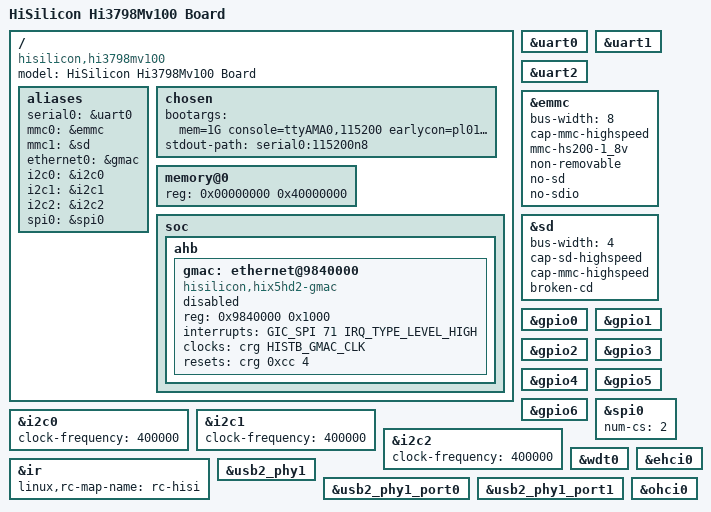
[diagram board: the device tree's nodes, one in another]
// SPDX-License-Identifier: GPL-2.0
/*
 * Device Tree for Hi3798Mv100 board
 * Based on vendor DTS decompiled from hi_kernel.bin
 * Adapted for mainline histb kernel
 */
/dts-v1/;

#include "hi3798mv100.dtsi"

/ {
	model = "HiSilicon Hi3798Mv100 Board";
	compatible = "hisilicon,hi3798mv100", "hisilicon,hi3798";

	aliases {
		serial0 = &uart0;
		mmc0 = &emmc;
		mmc1 = &sd;
		ethernet0 = &gmac;
		i2c0 = &i2c0;
		i2c1 = &i2c1;
		i2c2 = &i2c2;
		spi0 = &spi0;
	};

	chosen {
		bootargs = "mem=1G console=ttyAMA0,115200 earlycon=pl011,mmio32,0xf8b00000 root=/dev/mmcblk0p9 rootfstype=ext4 rootwait";
		stdout-path = "serial0:115200n8";
	};

	memory@0 {
		device_type = "memory";
		reg = <0x00000000 0x40000000>; /* 1GB */
	};
};

/* UART0 - Primary console */
&uart0 {
	status = "okay";
};

/* UART1 */
&uart1 {
	status = "okay";
};

/* UART2 */
&uart2 {
	status = "okay";
};

/* eMMC - Internal storage (non-removable) */
&emmc {
	status = "okay";
	bus-width = <8>;
	cap-mmc-highspeed;
	mmc-hs200-1_8v;
	non-removable;
	no-sd;
	no-sdio;
};

/* SD card slot */
&sd {
	status = "okay";
	bus-width = <4>;
	cap-sd-highspeed;
	cap-mmc-highspeed;
	broken-cd; /* Use polling if no card detect GPIO */
};

/* GPIO blocks used on this board */
&gpio0 { status = "okay"; };
&gpio1 { status = "okay"; };
&gpio2 { status = "okay"; };
&gpio3 { status = "okay"; };
&gpio4 { status = "okay"; };
&gpio5 { status = "okay"; };
&gpio6 { status = "okay"; };

/* I2C buses */
&i2c0 {
	status = "okay";
	clock-frequency = <400000>;
};

&i2c1 {
	status = "okay";
	clock-frequency = <400000>;
};

&i2c2 {
	status = "okay";
	clock-frequency = <400000>;
};

/* SPI0 */
&spi0 {
	status = "okay";
	num-cs = <2>;
};

/* Watchdog */
&wdt0 {
	status = "okay";
};

/* IR receiver */
&ir {
	status = "okay";
	linux,rc-map-name = "rc-hisi";
};

// SPDX-License-Identifier: GPL-2.0
/*
 * GMAC overlay for Hi3798Mv100
 * The mainline dtsi doesn't include the GMAC node yet,
 * so we define it based on vendor data.
 */

/ {
	soc {
		ahb {
			gmac: ethernet@9840000 {
				compatible = "hisilicon,hix5hd2-gmac";
				reg = <0x9840000 0x1000>;
				interrupts = <GIC_SPI 71 IRQ_TYPE_LEVEL_HIGH>;
				clocks = <&crg HISTB_GMAC_CLK>;
				clock-names = "apb_pclk";
				resets = <&crg 0xcc 4>;
				reset-names = "reset";
				status = "disabled";
			};
		};
	};
};

&usb2_phy1 { status = "okay"; };
&usb2_phy1_port0 { status = "okay"; };
&usb2_phy1_port1 { status = "okay"; };
&ehci0 { status = "okay"; };
&ohci0 { status = "okay"; };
